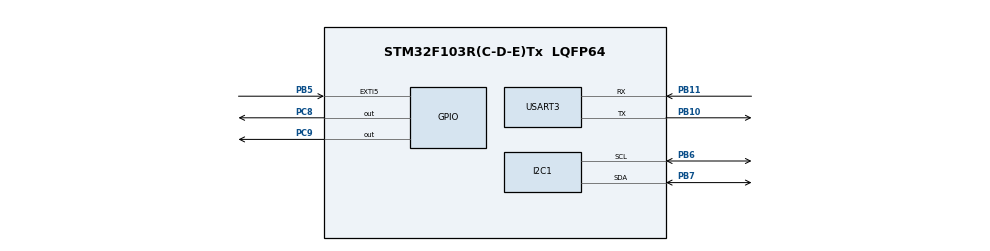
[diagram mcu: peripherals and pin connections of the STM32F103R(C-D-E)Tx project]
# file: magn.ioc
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FREERTOS.Tasks01=blinkTask,24,128,StartBlinkTask,Default,NULL,Dynamic,NULL,NULL;cliTask,8,128,StartCliTask,Default,NULL,Dynamic,NULL,NULL
FREERTOS.configUSE_NEWLIB_REENTRANT=1
I2C1.I2C_Mode=I2C_Fast
Mcu.Family=STM32F1
Mcu.Name=STM32F103R(C-D-E)Tx
Mcu.Package=LQFP64
NVIC.PriorityGroup=NVIC_PRIORITYGROUP_4
NVIC.TIM6_IRQn=true\:15\:0\:false\:false\:true\:false\:false\:true
NVIC.TimeBase=TIM6_IRQn
NVIC.TimeBaseIP=TIM6
PA13.Mode=Serial_Wire
PA13.Signal=SYS_JTMS-SWDIO
PA14.Mode=Serial_Wire
PA14.Signal=SYS_JTCK-SWCLK
PB10.Mode=Asynchronous
PB10.Signal=USART3_TX
PB11.Mode=Asynchronous
PB11.Signal=USART3_RX
PB5.Signal=GPXTI5
PB6.Mode=I2C
PB6.Signal=I2C1_SCL
PB7.Mode=I2C
PB7.Signal=I2C1_SDA
PC8.Signal=GPIO_Output
PC9.Signal=GPIO_Output
PD0-OSC_IN.Mode=HSE-External-Oscillator
PD0-OSC_IN.Signal=RCC_OSC_IN
PD1-OSC_OUT.Mode=HSE-External-Oscillator
PD1-OSC_OUT.Signal=RCC_OSC_OUT
ProjectManager.HeapSize=0x200
ProjectManager.StackSize=0x400
ProjectManager.TargetToolchain=STM32CubeIDE
RCC.AHBFreq_Value=72000000
RCC.APB1CLKDivider=RCC_HCLK_DIV2
RCC.APB1Freq_Value=36000000
RCC.APB1TimFreq_Value=72000000
RCC.APB2Freq_Value=72000000
RCC.APB2TimFreq_Value=72000000
RCC.EnbaleCSS=true
RCC.HCLKFreq_Value=72000000
RCC.PLLMUL=RCC_PLL_MUL9
RCC.PLLSourceVirtual=RCC_PLLSOURCE_HSE
RCC.SYSCLKFreq_VALUE=72000000
RCC.SYSCLKSource=RCC_SYSCLKSOURCE_PLLCLK
RCC.USBFreq_Value=72000000
USART3.VirtualMode=VM_ASYNC
VP_FREERTOS_VS_CMSIS_V2.Mode=CMSIS_V2
VP_SYS_VS_tim6.Mode=TIM6
board=custom

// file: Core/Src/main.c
/* USER CODE BEGIN Header */
/**
  ******************************************************************************
  * @file           : main.c
  * @brief          : Main program body
  ******************************************************************************
  * @attention
  *
  * Copyright (c) 2022 STMicroelectronics.
  * All rights reserved.
  *
  * This software is licensed under terms that can be found in the LICENSE file
  * in the root directory of this software component.
  * If no LICENSE file comes with this software, it is provided AS-IS.
  *
  ******************************************************************************
  */
/* USER CODE END Header */
#include "main.h"
#include "cmsis_os.h"
#include "i2c.h"
#include "usart.h"
#include "gpio.h"

void SystemClock_Config(void);
void MX_FREERTOS_Init(void);

int main(void)
{

  /* MCU Configuration--------------------------------------------------------*/

  /* Reset of all peripherals, Initializes the Flash interface and the Systick. */
  HAL_Init();

  /* Configure the system clock */
  SystemClock_Config();

  /* Initialize all configured peripherals */
  MX_GPIO_Init();
  MX_I2C1_Init();
  MX_USART3_UART_Init();

  /* Init scheduler */
  osKernelInitialize();  /* Call init function for freertos objects (in freertos.c) */
  MX_FREERTOS_Init();
  /* Start scheduler */
  osKernelStart();

  /* We should never get here as control is now taken by the scheduler */
  /* Infinite loop */
  while (1)
  {

  }
}

void SystemClock_Config(void)
{
  LL_FLASH_SetLatency(LL_FLASH_LATENCY_2);
  while(LL_FLASH_GetLatency()!= LL_FLASH_LATENCY_2)
  {
  }
  LL_RCC_HSE_Enable();

   /* Wait till HSE is ready */
  while(LL_RCC_HSE_IsReady() != 1)
  {

  }
  LL_RCC_HSE_EnableCSS();
  LL_RCC_PLL_ConfigDomain_SYS(LL_RCC_PLLSOURCE_HSE_DIV_1, LL_RCC_PLL_MUL_9);
  LL_RCC_PLL_Enable();

   /* Wait till PLL is ready */
  while(LL_RCC_PLL_IsReady() != 1)
  {

  }
  LL_RCC_SetAHBPrescaler(LL_RCC_SYSCLK_DIV_1);
  LL_RCC_SetAPB1Prescaler(LL_RCC_APB1_DIV_2);
  LL_RCC_SetAPB2Prescaler(LL_RCC_APB2_DIV_1);
  LL_RCC_SetSysClkSource(LL_RCC_SYS_CLKSOURCE_PLL);

   /* Wait till System clock is ready */
  while(LL_RCC_GetSysClkSource() != LL_RCC_SYS_CLKSOURCE_STATUS_PLL)
  {

  }
  LL_SetSystemCoreClock(72000000);

   /* Update the time base */
  if (HAL_InitTick (TICK_INT_PRIORITY) != HAL_OK)
  {
    Error_Handler();
  }
}

void HAL_TIM_PeriodElapsedCallback(TIM_HandleTypeDef *htim)
{
  if (htim->Instance == TIM6) {
    HAL_IncTick();
  }
}

void Error_Handler(void)
{
  __disable_irq();
  while (1)
  {
  }
}

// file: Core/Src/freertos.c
/* USER CODE BEGIN Header */
/**
  ******************************************************************************
  * File Name          : freertos.c
  * Description        : Code for freertos applications
  ******************************************************************************
  * @attention
  *
  * Copyright (c) 2022 STMicroelectronics.
  * All rights reserved.
  *
  * This software is licensed under terms that can be found in the LICENSE file
  * in the root directory of this software component.
  * If no LICENSE file comes with this software, it is provided AS-IS.
  *
  ******************************************************************************
  */
/* USER CODE END Header */

#include "FreeRTOS.h"
#include "task.h"
#include "main.h"
#include "cmsis_os.h"

/* Definitions for blinkTask */
osThreadId_t blinkTaskHandle;
const osThreadAttr_t blinkTask_attributes = {
  .name = "blinkTask",
  .stack_size = 128 * 4,
  .priority = (osPriority_t) osPriorityNormal,
};
/* Definitions for cliTask */
osThreadId_t cliTaskHandle;
const osThreadAttr_t cliTask_attributes = {
  .name = "cliTask",
  .stack_size = 128 * 4,
  .priority = (osPriority_t) osPriorityLow,
};

void StartBlinkTask(void *argument);
void StartCliTask(void *argument);

void MX_FREERTOS_Init(void); /* (MISRA C 2004 rule 8.1) */

void MX_FREERTOS_Init(void) {

  /* Create the thread(s) */
  /* creation of blinkTask */
  blinkTaskHandle = osThreadNew(StartBlinkTask, NULL, &blinkTask_attributes);

  /* creation of cliTask */
  cliTaskHandle = osThreadNew(StartCliTask, NULL, &cliTask_attributes);

}

void StartBlinkTask(void *argument)
{
  /* USER CODE BEGIN StartBlinkTask */
  /* Infinite loop */
  for(;;)
  {
      GPIOC->ODR ^= GPIO_PIN_8;
      osDelay(1000);
  }
  /* USER CODE END StartBlinkTask */
}

void StartCliTask(void *argument)
{
  for(;;)
  {
    osDelay(1);
  }
}
